VERSION ""

NS_ :

BS_:

BU_: BMS Third_Party_Device

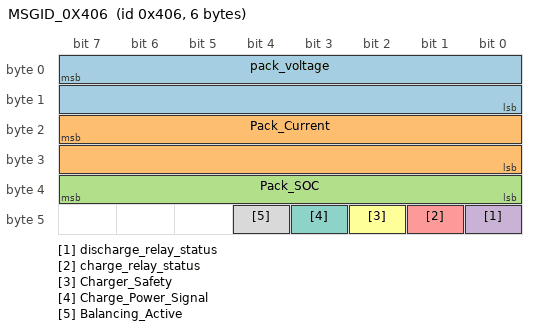
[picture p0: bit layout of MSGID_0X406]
BO_ 1030 MSGID_0X406: 6 BMS
 SG_ pack_voltage : 7|16@0+ (0.1,0) [0|0] "Volts"  Third_Party_Device
 SG_ Pack_Current : 23|16@0+ (0.1,0) [0|0] "Amps"  Third_Party_Device
 SG_ Pack_SOC : 39|8@0+ (0.5,0) [0|0] "Percent"  Third_Party_Device
 SG_ discharge_relay_status : 40|1@1+ (1,0) [0|1] ""  Third_Party_Device
 SG_ charge_relay_status : 41|1@1+ (1,0) [0|1] ""  Third_Party_Device
 SG_ Charger_Safety : 42|1@1+ (1,0) [0|1] ""  Third_Party_Device
 SG_ Charge_Power_Signal : 43|1@1+ (1,0) [0|1] ""  Third_Party_Device
 SG_ Balancing_Active : 44|1@1+ (1,0) [0|1] ""  Third_Party_Device

BO_ 262 MSGID_0X106: 3 BMS
 SG_ DTC_P0A1F_Internal_Cell_Communication_Fault : 0|1@1+ (1,0) [0|1] ""  Third_Party_Device
 SG_ Weak_Cell_Fault : 1|1@1+ (1,0) [0|1] ""  Third_Party_Device
 SG_ Low_Cell_Voltage_Fault : 2|1@1+ (1,0) [0|1] ""  Third_Party_Device
 SG_ Cell_Open_Wiring_Fault : 3|1@1+ (1,0) [0|1] ""  Third_Party_Device
 SG_ Current_Sensor_Fault : 4|1@1+ (1,0) [0|1] ""  Third_Party_Device
 SG_ Weak_Pack_Fault : 5|1@1+ (1,0) [0|1] ""  Third_Party_Device
 SG_ Thermistor_Fault : 6|1@1+ (1,0) [0|1] ""  Third_Party_Device
 SG_ CAN_Communication_Fault : 7|1@1+ (1,0) [0|1] ""  Third_Party_Device
 SG_ Redundant_Power_Supply_Fault : 8|1@1+ (1,0) [0|1] ""  Third_Party_Device
 SG_ High_Voltage_Isolation_Fault : 9|1@1+ (1,0) [0|1] ""  Third_Party_Device
 SG_ ChargeEnable_Relay_Fault : 10|1@1+ (1,0) [0|1] ""  Third_Party_Device
 SG_ DischargeEnable_Relay_Fault : 11|1@1+ (1,0) [0|1] ""  Third_Party_Device
 SG_ Internal_Hardware_Fault : 12|1@1+ (1,0) [0|1] ""  Third_Party_Device
 SG_ DTC_P0A0A_Internal_Heatsink_Thermistor_Fault : 13|1@1+ (1,0) [0|1] ""  Third_Party_Device
 SG_ Internal_Logic_Fault : 14|1@1+ (1,0) [0|1] ""  Third_Party_Device
 SG_ DTC_P0A0C_Highest_Cell_Voltage_Too_High_Fault : 16|1@1+ (1,0) [0|1] ""  Third_Party_Device
 SG_ DTC_P0A0E_Lowest_Cell_Voltage_Too_Low_Fault : 17|1@1+ (1,0) [0|1] ""  Third_Party_Device
 SG_ Pack_Too_Hot_Fault : 18|1@1+ (1,0) [0|1] ""  Third_Party_Device

CM_ BO_ 1030 "This ID Transmits at 8 ms.";
CM_ BO_ 262 "This ID Transmits at 8 ms.";
CM_ SG_ 262 DTC_P0A1F_Internal_Cell_Communication_Fault "fault";
CM_ SG_ 262 Low_Cell_Voltage_Fault "fault";
CM_ SG_ 262 Current_Sensor_Fault "fault";
CM_ SG_ 262 Weak_Pack_Fault "fault";
CM_ SG_ 262 Thermistor_Fault "fault";
CM_ SG_ 262 CAN_Communication_Fault "fault";
CM_ SG_ 262 Redundant_Power_Supply_Fault "fault";
CM_ SG_ 262 High_Voltage_Isolation_Fault "fault";
CM_ SG_ 262 ChargeEnable_Relay_Fault "fault";
CM_ SG_ 262 DischargeEnable_Relay_Fault "fault";
CM_ SG_ 262 Internal_Hardware_Fault "fault";
CM_ SG_ 262 DTC_P0A0A_Internal_Heatsink_Thermistor_Fault "fault";
CM_ SG_ 262 Internal_Logic_Fault "fault";
CM_ SG_ 262 DTC_P0A0C_Highest_Cell_Voltage_Too_High_Fault "fault";
CM_ SG_ 262 DTC_P0A0E_Lowest_Cell_Voltage_Too_Low_Fault "fault";
CM_ SG_ 262 Pack_Too_Hot_Fault "fault";
